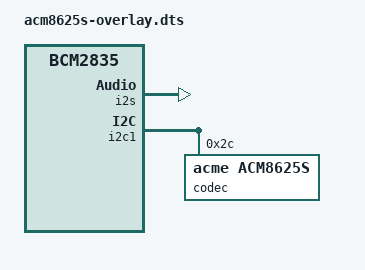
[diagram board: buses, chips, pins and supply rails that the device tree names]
// Definitions for AmpliMuseAmp
// compile:             dtc -I dts -O dtb -o /boot/overlays/tas5805m.dtbo tas5805m-overlay.dts
// bash:                sudo dtoverlay tas5805m i2creg=0x2c firmware=default
// /boot/config.txt:    dtoverlay=tas5805m,i2creg=0x2c,firmware=default
// i2creg: TAS5805M@0x2c, TAS5806M@0x2c, TAS5806MD@0x2c, TAS5822M@0x2c, TAS5825M@0x4c, TAS5825P@0x4c, TAS5828M@0x60
/dts-v1/;
/plugin/;

/ {
    compatible = "brcm,bcm2835";

    fragment@0 {
        target = <&i2s>;
        __overlay__ {
            status = "okay";
        };
    };

    fragment@1 {
        target = <&i2c1>;
        __overlay__ {
            status = "okay";
            #address-cells = <1>;
            #size-cells = <0>;

            codec: acm8625s@2c {
                #sound-dai-cells = <0>;
                compatible = "acme,acm8625s";
                reg = <0x2c>;
            };
        };
    };

//     fragment@2 {
//         target = <&sound>;
//         __overlay__ {
//             status = "okay";
//             compatible = "simple-audio-card";
//             label = "AmpliMuseAmp";
//             simple-audio-card,dai-link {
//                 /* DAC */
//                 format = "i2s";
//                 bitclock-master = <&dailink_master>;
//                 frame-master = <&dailink_master>;
//                 dailink_master: cpu {
//                         sound-dai = <&i2s>;
//                         dai-tdm-slot-num = <2>;
//                         dai-tdm-slot-width = <32>;
//                 };
//             codec {
//                     sound-dai = <&codec>;
//             };
//         };
//     };

//   };
};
